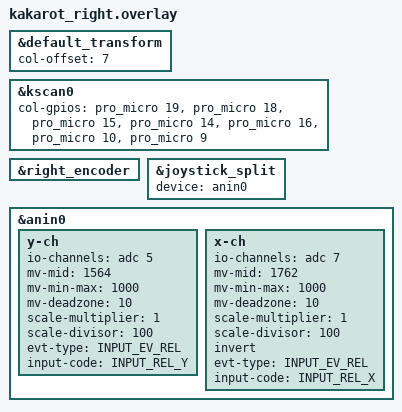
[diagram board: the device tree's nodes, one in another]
#include "kakarot.dtsi" // The shared dtsi file is included in the overlay

&default_transform {
    col-offset = <7>;
};

// Label of the kscan node in the dtsi
&kscan0 {
    col-gpios    
        = <&pro_micro 19 GPIO_ACTIVE_HIGH>
        , <&pro_micro 18 GPIO_ACTIVE_HIGH>
        , <&pro_micro 15 GPIO_ACTIVE_HIGH>
        , <&pro_micro 14 GPIO_ACTIVE_HIGH>
        , <&pro_micro 16 GPIO_ACTIVE_HIGH>
        , <&pro_micro 10 GPIO_ACTIVE_HIGH>
        , <&pro_micro 9 GPIO_ACTIVE_HIGH>
        ;
};

&right_encoder {
    status = "okay";
};


&joystick_split {
    device = <&anin0>;
};

&anin0 {
     y-ch {
            io-channels = <&adc 5>; // <--- see ain-map.png for nRF52840
            mv-mid = <1564>;
            mv-min-max = <1000>;
            mv-deadzone = <10>;
            scale-multiplier = <1>;
            scale-divisor = <100>;
            //invert;
            evt-type = <INPUT_EV_REL>;
            input-code = <INPUT_REL_Y>;
        };
        x-ch {
            io-channels = <&adc 7>; // <--- see ain-map.png for nRF52840
            mv-mid = <1762>;
            mv-min-max = <1000>;
            mv-deadzone = <10>;
            scale-multiplier = <1>;
            scale-divisor = <100>;
            invert;
            evt-type = <INPUT_EV_REL>;
            input-code = <INPUT_REL_X>;

            /* enable report mode for gamepad axis or knob */
            /* to only call input_report on quantquantized value is updated */
            /* NOTE: mouse input does NOT need this */
            // report-on-change-only;

        };
};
